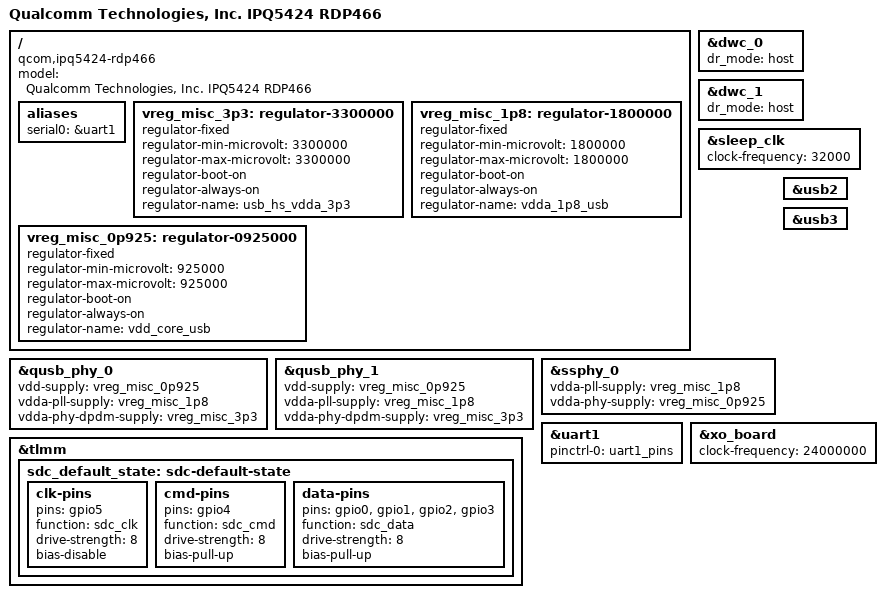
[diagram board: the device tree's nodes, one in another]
// SPDX-License-Identifier: GPL-2.0+ OR BSD-3-Clause
/*
 * IPQ5424 RDP466 board device tree source
 *
 * Copyright (c) 2024 The Linux Foundation. All rights reserved.
 */

/dts-v1/;

#include "ipq5424.dtsi"

/ {
	model = "Qualcomm Technologies, Inc. IPQ5424 RDP466";
	compatible = "qcom,ipq5424-rdp466", "qcom,ipq5424";

	aliases {
		serial0 = &uart1;
	};

	vreg_misc_3p3: regulator-3300000 {
		compatible = "regulator-fixed";
		regulator-min-microvolt = <3300000>;
		regulator-max-microvolt = <3300000>;
		regulator-boot-on;
		regulator-always-on;
		regulator-name = "usb_hs_vdda_3p3";
	};

	vreg_misc_1p8: regulator-1800000 {
		compatible = "regulator-fixed";
		regulator-min-microvolt = <1800000>;
		regulator-max-microvolt = <1800000>;
		regulator-boot-on;
		regulator-always-on;
		regulator-name = "vdda_1p8_usb";
	};

	vreg_misc_0p925: regulator-0925000 {
		compatible = "regulator-fixed";
		regulator-min-microvolt = <925000>;
		regulator-max-microvolt = <925000>;
		regulator-boot-on;
		regulator-always-on;
		regulator-name = "vdd_core_usb";
	};
};

&dwc_0 {
	dr_mode = "host";
};

&dwc_1 {
	dr_mode = "host";
};

&qusb_phy_0 {
	vdd-supply = <&vreg_misc_0p925>;
	vdda-pll-supply = <&vreg_misc_1p8>;
	vdda-phy-dpdm-supply = <&vreg_misc_3p3>;

	status = "okay";
};

&qusb_phy_1 {
	vdd-supply = <&vreg_misc_0p925>;
	vdda-pll-supply = <&vreg_misc_1p8>;
	vdda-phy-dpdm-supply = <&vreg_misc_3p3>;

	status = "okay";
};

&sleep_clk {
	clock-frequency = <32000>;
};

&ssphy_0 {
	vdda-pll-supply = <&vreg_misc_1p8>;
	vdda-phy-supply = <&vreg_misc_0p925>;

	status = "okay";
};

&tlmm {
	sdc_default_state: sdc-default-state {
		clk-pins {
			pins = "gpio5";
			function = "sdc_clk";
			drive-strength = <8>;
			bias-disable;
		};

		cmd-pins {
			pins = "gpio4";
			function = "sdc_cmd";
			drive-strength = <8>;
			bias-pull-up;
		};

		data-pins {
			pins = "gpio0", "gpio1", "gpio2", "gpio3";
			function = "sdc_data";
			drive-strength = <8>;
			bias-pull-up;
		};
	};
};

&uart1 {
	pinctrl-0 = <&uart1_pins>;
	pinctrl-names = "default";
	status = "okay";
};

&usb2 {
	status = "okay";
};

&usb3 {
	status = "okay";
};

&xo_board {
	clock-frequency = <24000000>;
};

